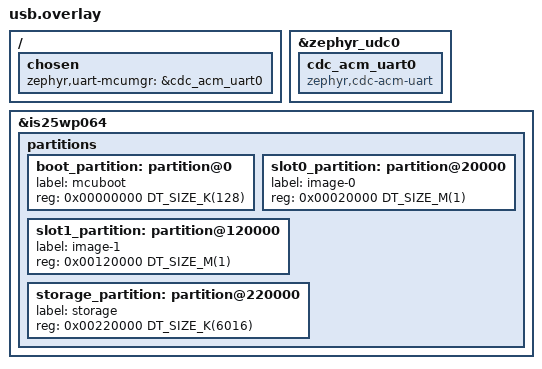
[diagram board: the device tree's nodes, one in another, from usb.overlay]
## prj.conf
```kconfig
# Enable MCUmgr and dependencies.
CONFIG_NET_BUF=y
CONFIG_ZCBOR=y
CONFIG_CRC=y
CONFIG_MCUMGR=y
CONFIG_STREAM_FLASH=y
CONFIG_FLASH_MAP=y

# Some command handlers require a large stack.
CONFIG_SYSTEM_WORKQUEUE_STACK_SIZE=2304
CONFIG_MAIN_STACK_SIZE=2048

# Ensure an MCUboot-compatible binary is generated.
CONFIG_BOOTLOADER_MCUBOOT=y

# Enable flash operations.
CONFIG_FLASH=y

# Required by the `taskstat` command.
CONFIG_THREAD_MONITOR=y

# Support for taskstat command
CONFIG_MCUMGR_GRP_OS_TASKSTAT=y

# Enable statistics and statistic names.
CONFIG_STATS=y
CONFIG_STATS_NAMES=y

# Enable most core commands.
CONFIG_FLASH=y
CONFIG_IMG_MANAGER=y
CONFIG_MCUMGR_GRP_IMG=y
CONFIG_MCUMGR_GRP_OS=y
CONFIG_MCUMGR_GRP_STAT=y

# Enable logging
CONFIG_LOG=y
CONFIG_MCUBOOT_UTIL_LOG_LEVEL_WRN=y

# Disable debug logging
CONFIG_LOG_MAX_LEVEL=3

# Ensure an MCUboot-compatible binary is generated.
CONFIG_BOOTLOADER_MCUBOOT=y
CONFIG_MCUBOOT_SIGNATURE_KEY_FILE="zephyrproject/bootloader/mcuboot/root-rsa-2048.pem"
```

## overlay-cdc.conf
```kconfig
# Enable USB subsystem
CONFIG_USB_DEVICE_STACK=y
CONFIG_SERIAL=y
CONFIG_UART_LINE_CTRL=y
CONFIG_USB_DEVICE_INITIALIZE_AT_BOOT=n
CONFIG_CONSOLE=y
# USB backend is serial device
CONFIG_MCUMGR_TRANSPORT_UART=y
CONFIG_BASE64=y



CONFIG_BOOTLOADER_MCUBOOT=y
CONFIG_MCUBOOT_SIGNATURE_KEY_FILE="/home/kuno/git/zephyrproject/bootloader/mcuboot/root-rsa-2048.pem"


CONFIG_WATCHDOG=y
CONFIG_WDT_DISABLE_AT_BOOT=n
```

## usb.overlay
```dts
/*
 * Copyright (c) 2021 Nordic Semiconductor ASA
 *
 * SPDX-License-Identifier: Apache-2.0
 */

/ {
	chosen {
		zephyr,uart-mcumgr = &cdc_acm_uart0;
	};
};

&zephyr_udc0 {
	cdc_acm_uart0: cdc_acm_uart0 {
		compatible = "zephyr,cdc-acm-uart";
	};
};

/delete-node/ &boot_partition;
/delete-node/ &slot0_partition;
/delete-node/ &slot1_partition;
/delete-node/ &scratch_partition;
/delete-node/ &storage_partition;

&is25wp064 {
    partitions {
        boot_partition: partition@0 {
            label = "mcuboot";
            reg = <0x00000000 DT_SIZE_K(128)>;
        };
        slot0_partition: partition@20000 {
            label = "image-0";
            reg = <0x00020000 DT_SIZE_M(1)>;
        };
        slot1_partition: partition@120000 {
            label = "image-1";
            reg = <0x00120000 DT_SIZE_M(1)>;
        };
        storage_partition: partition@220000 {
            label = "storage";
            reg = <0x00220000 DT_SIZE_K(6016)>;
        };
    };
};
```

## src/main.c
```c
/*
 * Copyright (c) 2012-2014 Wind River Systems, Inc.
 * Copyright (c) 2020 Prevas A/S
 *
 * SPDX-License-Identifier: Apache-2.0
 */

#include <zephyr/kernel.h>
#include <zephyr/stats/stats.h>
#include <zephyr/usb/usb_device.h>

#include <zephyr/device.h>
#include <zephyr/drivers/watchdog.h>

#ifdef CONFIG_MCUMGR_GRP_FS
#include <zephyr/device.h>
#include <zephyr/fs/fs.h>
#include <zephyr/fs/littlefs.h>
#endif
#ifdef CONFIG_MCUMGR_GRP_STAT
#include <zephyr/mgmt/mcumgr/grp/stat_mgmt/stat_mgmt.h>
#endif

#define LOG_LEVEL LOG_LEVEL_DBG
#include <zephyr/logging/log.h>
LOG_MODULE_REGISTER(smp_sample);

#include "common.h"

#define STORAGE_PARTITION_LABEL	storage_partition
#define STORAGE_PARTITION_ID	FIXED_PARTITION_ID(STORAGE_PARTITION_LABEL)

/* Define an example stats group; approximates seconds since boot. */
STATS_SECT_START(smp_svr_stats)
STATS_SECT_ENTRY(ticks)
STATS_SECT_END;

/* Assign a name to the `ticks` stat. */
STATS_NAME_START(smp_svr_stats)
STATS_NAME(smp_svr_stats, ticks)
STATS_NAME_END(smp_svr_stats);

/* Define an instance of the stats group. */
STATS_SECT_DECL(smp_svr_stats) smp_svr_stats;

#ifdef CONFIG_MCUMGR_GRP_FS
FS_LITTLEFS_DECLARE_DEFAULT_CONFIG(cstorage);
static struct fs_mount_t littlefs_mnt = {
	.type = FS_LITTLEFS,
	.fs_data = &cstorage,
	.storage_dev = (void *)STORAGE_PARTITION_ID,
	.mnt_point = "/lfs1"
};
#endif

#define WDT_MAX_WINDOW  1000U
#define WDT_MIN_WINDOW  0U

int main(void)
{
	int rc = STATS_INIT_AND_REG(smp_svr_stats, STATS_SIZE_32,
				    "smp_svr_stats");

	if (rc < 0) {
		LOG_ERR("Error initializing stats system [%d]", rc);
	}

	int err;
	int wdt_channel_id;
	const struct device *const wdt = DEVICE_DT_GET(DT_ALIAS(watchdog0));

	printk("Watchdog sample application\n");

	if (!device_is_ready(wdt)) {
		printk("%s: device not ready.\n", wdt->name);
		return 0;
	}

	struct wdt_timeout_cfg wdt_config = {
		/* Reset SoC when watchdog timer expires. */
		.flags = WDT_FLAG_RESET_SOC,

		/* Expire watchdog after max window */
		.window.min = WDT_MIN_WINDOW,
		.window.max = WDT_MAX_WINDOW,
	};

	wdt_channel_id = wdt_install_timeout(wdt, &wdt_config);
	if (wdt_channel_id < 0) {
		printk("Watchdog install error\n");
		return 0;
	}

	err = wdt_setup(wdt, WDT_OPT_PAUSE_HALTED_BY_DBG);
	if (err < 0) {
		printk("Watchdog setup error\n");
		return 0;
	}

	/* Register the built-in mcumgr command handlers. */
#ifdef CONFIG_MCUMGR_GRP_FS
	rc = fs_mount(&littlefs_mnt);
	if (rc < 0) {
		LOG_ERR("Error mounting littlefs [%d]", rc);
	}
#endif

#ifdef CONFIG_MCUMGR_TRANSPORT_BT
	start_smp_bluetooth_adverts();
#endif

	if (IS_ENABLED(CONFIG_USB_DEVICE_STACK)) {
		rc = usb_enable(NULL);
		if (rc) {
			LOG_ERR("Failed to enable USB");
			return 0;
		}
	}
	/* using __TIME__ ensure that a new binary will be built on every
	 * compile which is convenient when testing firmware upgrade.
	 */
	LOG_INF("build time: " __DATE__ " " __TIME__);

	/* The system work queue handles all incoming mcumgr requests.  Let the
	 * main thread idle while the mcumgr server runs.
	 */
	while (1) {
		k_sleep(K_MSEC(500));
		STATS_INC(smp_svr_stats, ticks);
		wdt_feed(wdt, wdt_channel_id);
	}
	return 0;
}
```
